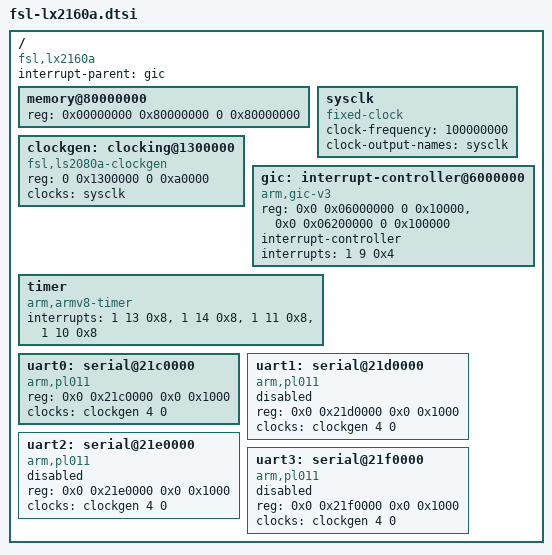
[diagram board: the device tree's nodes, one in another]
/*
 * NXP lx2160a SOC common device tree source
 *
 * Copyright 2018 NXP
 *
 * SPDX-License-Identifier:	GPL-2.0+
 */

/ {
	compatible = "fsl,lx2160a";
	interrupt-parent = <&gic>;
	#address-cells = <2>;
	#size-cells = <2>;

	memory@80000000 {
		device_type = "memory";
		reg = <0x00000000 0x80000000 0 0x80000000>;
		      /* DRAM space - 1, size : 2 GB DRAM */
	};

	sysclk: sysclk {
		compatible = "fixed-clock";
		#clock-cells = <0>;
		clock-frequency = <100000000>;
		clock-output-names = "sysclk";
	};

	clockgen: clocking@1300000 {
		compatible = "fsl,ls2080a-clockgen";
		reg = <0 0x1300000 0 0xa0000>;
		#clock-cells = <2>;
		clocks = <&sysclk>;
	};

	gic: interrupt-controller@6000000 {
		compatible = "arm,gic-v3";
		reg = <0x0 0x06000000 0 0x10000>, /* GIC Dist */
		      <0x0 0x06200000 0 0x100000>; /* GICR */
		#interrupt-cells = <3>;
		interrupt-controller;
		interrupts = <1 9 0x4>;
	};

	timer {
		compatible = "arm,armv8-timer";
		interrupts = <1 13 0x8>, /* Physical Secure PPI, active-low */
			     <1 14 0x8>, /* Physical NS PPI, active-low */
			     <1 11 0x8>, /* Virtual PPI, active-low */
			     <1 10 0x8>; /* Hypervisor PPI, active-low */
	};

	uart0: serial@21c0000 {
		compatible = "arm,pl011";
		reg = <0x0 0x21c0000 0x0 0x1000>;
		clocks = <&clockgen 4 0>;
	};

	uart1: serial@21d0000 {
		compatible = "arm,pl011";
		reg = <0x0 0x21d0000 0x0 0x1000>;
		clocks = <&clockgen 4 0>;
		status = "disabled";
	};

	uart2: serial@21e0000 {
		compatible = "arm,pl011";
		reg = <0x0 0x21e0000 0x0 0x1000>;
		clocks = <&clockgen 4 0>;
		status = "disabled";
	};

	uart3: serial@21f0000 {
		compatible = "arm,pl011";
		reg = <0x0 0x21f0000 0x0 0x1000>;
		clocks = <&clockgen 4 0>;
		status = "disabled";
	};
};
